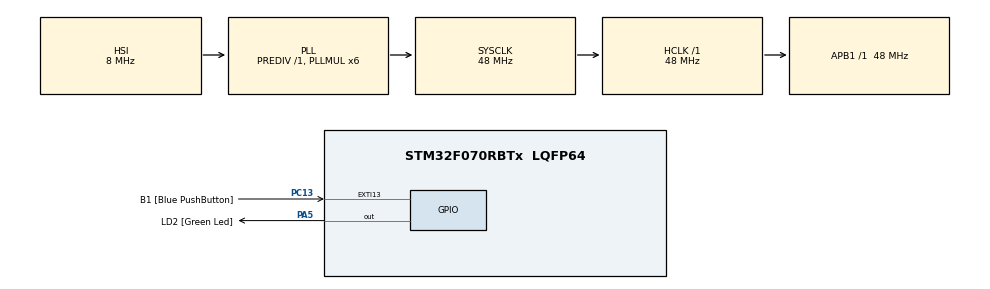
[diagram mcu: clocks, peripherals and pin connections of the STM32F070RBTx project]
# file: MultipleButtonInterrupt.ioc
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Mcu.Family=STM32F0
Mcu.Name=STM32F070RBTx
Mcu.Package=LQFP64
PA13.GPIO_Label=TMS
PA13.Mode=Serial_Wire
PA13.Signal=SYS_SWDIO
PA14.GPIO_Label=TCK
PA14.Mode=Serial_Wire
PA14.Signal=SYS_SWCLK
PA5.GPIO_Label=LD2 [Green Led]
PA5.Signal=GPIO_Output
PC13.GPIO_Label=B1 [Blue PushButton]
PC13.GPIO_ModeDefaultEXTI=GPIO_MODE_IT_FALLING
PC13.Signal=GPXTI13
PC14-OSC32_IN.GPIO_Label=RCC_OSC32_IN
PC14-OSC32_IN.Mode=LSE-External-Oscillator
PC14-OSC32_IN.Signal=RCC_OSC32_IN
PC15-OSC32_OUT.GPIO_Label=RCC_OSC32_OUT
PC15-OSC32_OUT.Mode=LSE-External-Oscillator
PC15-OSC32_OUT.Signal=RCC_OSC32_OUT
PF0-OSC_IN.GPIO_Label=RCC_OSC_IN
PF0-OSC_IN.Mode=HSE-External-Clock-Source
PF0-OSC_IN.Signal=RCC_OSC_IN
PF1-OSC_OUT.GPIO_Label=RCC_OSC_OUT
PF1-OSC_OUT.Signal=RCC_OSC_OUT
ProjectManager.HeapSize=0x200
ProjectManager.StackSize=0x400
ProjectManager.TargetToolchain=STM32CubeIDE
RCC.AHBFreq_Value=48000000
RCC.APB1Freq_Value=48000000
RCC.APB1TimFreq_Value=48000000
RCC.HCLKFreq_Value=48000000
RCC.PLLMUL=RCC_PLL_MUL6
RCC.SYSCLKFreq_VALUE=48000000
RCC.SYSCLKSource=RCC_SYSCLKSOURCE_PLLCLK
board=NUCLEO-F070RB

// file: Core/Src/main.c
/* USER CODE BEGIN Header */
/**
  ******************************************************************************
  * @file           : main.c
  * @brief          : Main program body
  ******************************************************************************
  * @attention
  *
  * <h2><center>&copy; Copyright (c) 2021 STMicroelectronics.
  * All rights reserved.</center></h2>
  *
  * This software component is licensed by ST under BSD 3-Clause license,
  * the "License"; You may not use this file except in compliance with the
  * License. You may obtain a copy of the License at:
  *                        opensource.org/licenses/BSD-3-Clause
  *
  ******************************************************************************
  */
/* USER CODE END Header */
#include "main.h"

void SystemClock_Config(void);
static void MX_GPIO_Init(void);
/* USER CODE BEGIN PFP */
void GPIOA_Config(){		// GPIOA, 5. pin active for led 2
	RCC->AHBENR |= 0x20000;

	GPIOA->MODER |= 0x400;
	GPIOA->OTYPER |= 0x0;
	GPIOA->OSPEEDR |= 0xC00;
	GPIOA->PUPDR |= 0x0;

}

void EXTIB1_Config(){		// B1 button interrupt configuration
	RCC->APB2ENR |= 0x1;

	SYSCFG->EXTICR[3] |= 0x20;

	NVIC_EnableIRQ(EXTI4_15_IRQn);
	NVIC_SetPriority(EXTI4_15_IRQn,7);

	EXTI->IMR |= 0x2000;
	EXTI->RTSR |= 0x2000;
}

void EXTIB2_Config(){		// B2 button interrupt configuration
	RCC->APB2ENR |= 0x1;

	SYSCFG->EXTICR[0] |= 0x1000;

	NVIC_EnableIRQ(EXTI2_3_IRQn);
	NVIC_SetPriority(EXTI2_3_IRQn,6);

	EXTI->IMR |= 0x8;
	EXTI->RTSR |= 0x8;
}
/* USER CODE END PFP */

/* USER CODE BEGIN 0 */
void EXTI4_15_IRQHandler(){		// B1, pin 13 interrupt first high led and then down
	if(EXTI->PR & 0x2000){
		GPIOA->ODR |= 0x20;
		HAL_Delay(5000);
		GPIOA->ODR = 0x0;
		HAL_Delay(1000);
		EXTI->PR = 0x2000;
	}
}

void EXTI2_3_IRQHandler(){		// B2, pin 3 interrupt first down led and then high
	if(EXTI->PR & 0x8){
		GPIOA->ODR = 0x0;
		HAL_Delay(1000);
		GPIOA->ODR |= 0x20;
		HAL_Delay(1000);
		EXTI->PR = 0x8;
	}
}
/* USER CODE END 0 */

int main(void)
{

  /* MCU Configuration--------------------------------------------------------*/

  /* Reset of all peripherals, Initializes the Flash interface and the Systick. */
  HAL_Init();

  /* Configure the system clock */
  SystemClock_Config();

  /* Initialize all configured peripherals */
  MX_GPIO_Init();
  /* USER CODE BEGIN 2 */
  GPIOA_Config();

  EXTIB1_Config();
  EXTIB2_Config();
  /* USER CODE END 2 */

  /* Infinite loop */
  while (1)
  {

  }
}

void SystemClock_Config(void)
{
  RCC_OscInitTypeDef RCC_OscInitStruct = {0};
  RCC_ClkInitTypeDef RCC_ClkInitStruct = {0};

  /** Initializes the RCC Oscillators according to the specified parameters
  * in the RCC_OscInitTypeDef structure.
  */
  RCC_OscInitStruct.OscillatorType = RCC_OSCILLATORTYPE_HSI;
  RCC_OscInitStruct.HSIState = RCC_HSI_ON;
  RCC_OscInitStruct.HSICalibrationValue = RCC_HSICALIBRATION_DEFAULT;
  RCC_OscInitStruct.PLL.PLLState = RCC_PLL_ON;
  RCC_OscInitStruct.PLL.PLLSource = RCC_PLLSOURCE_HSI;
  RCC_OscInitStruct.PLL.PLLMUL = RCC_PLL_MUL6;
  RCC_OscInitStruct.PLL.PREDIV = RCC_PREDIV_DIV1;
  if (HAL_RCC_OscConfig(&RCC_OscInitStruct) != HAL_OK)
  {
    Error_Handler();
  }
  /** Initializes the CPU, AHB and APB buses clocks
  */
  RCC_ClkInitStruct.ClockType = RCC_CLOCKTYPE_HCLK|RCC_CLOCKTYPE_SYSCLK
                              |RCC_CLOCKTYPE_PCLK1;
  RCC_ClkInitStruct.SYSCLKSource = RCC_SYSCLKSOURCE_PLLCLK;
  RCC_ClkInitStruct.AHBCLKDivider = RCC_SYSCLK_DIV1;
  RCC_ClkInitStruct.APB1CLKDivider = RCC_HCLK_DIV1;

  if (HAL_RCC_ClockConfig(&RCC_ClkInitStruct, FLASH_LATENCY_1) != HAL_OK)
  {
    Error_Handler();
  }
}

static void MX_GPIO_Init(void)
{
  GPIO_InitTypeDef GPIO_InitStruct = {0};

  /* GPIO Ports Clock Enable */
  __HAL_RCC_GPIOC_CLK_ENABLE();
  __HAL_RCC_GPIOF_CLK_ENABLE();
  __HAL_RCC_GPIOA_CLK_ENABLE();

  /*Configure GPIO pin Output Level */
  HAL_GPIO_WritePin(LD2_GPIO_Port, LD2_Pin, GPIO_PIN_RESET);

  /*Configure GPIO pin : B1_Pin */
  GPIO_InitStruct.Pin = B1_Pin;
  GPIO_InitStruct.Mode = GPIO_MODE_IT_FALLING;
  GPIO_InitStruct.Pull = GPIO_NOPULL;
  HAL_GPIO_Init(B1_GPIO_Port, &GPIO_InitStruct);

  /*Configure GPIO pin : LD2_Pin */
  GPIO_InitStruct.Pin = LD2_Pin;
  GPIO_InitStruct.Mode = GPIO_MODE_OUTPUT_PP;
  GPIO_InitStruct.Pull = GPIO_NOPULL;
  GPIO_InitStruct.Speed = GPIO_SPEED_FREQ_LOW;
  HAL_GPIO_Init(LD2_GPIO_Port, &GPIO_InitStruct);

}

void Error_Handler(void)
{
  __disable_irq();
  while (1)
  {
  }
}

/************************ (C) COPYRIGHT STMicroelectronics *****END OF FILE****/
